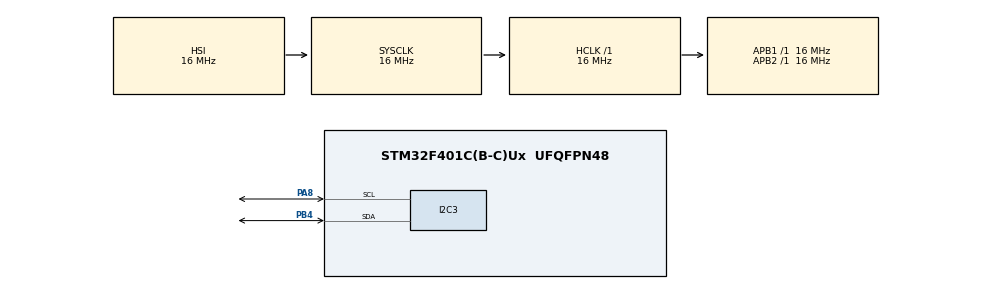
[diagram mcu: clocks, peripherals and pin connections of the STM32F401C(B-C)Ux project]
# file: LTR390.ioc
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FREERTOS.Tasks01=defaultTask,24,128,StartDefaultTask,Default,NULL,Dynamic,NULL,NULL
FREERTOS.configUSE_NEWLIB_REENTRANT=1
Mcu.Family=STM32F4
Mcu.Name=STM32F401C(B-C)Ux
Mcu.Package=UFQFPN48
NVIC.I2C3_ER_IRQn=true\:5\:0\:false\:false\:true\:true\:true\:true\:true
NVIC.I2C3_EV_IRQn=true\:5\:0\:false\:false\:true\:true\:true\:true\:true
NVIC.PriorityGroup=NVIC_PRIORITYGROUP_4
NVIC.TIM4_IRQn=true\:15\:0\:false\:false\:true\:false\:false\:true\:true
NVIC.TimeBase=TIM4_IRQn
NVIC.TimeBaseIP=TIM4
PA13.Mode=Trace_Asynchronous_SW
PA13.Signal=SYS_JTMS-SWDIO
PA14.Mode=Trace_Asynchronous_SW
PA14.Signal=SYS_JTCK-SWCLK
PA8.Mode=I2C
PA8.Signal=I2C3_SCL
PB3.Mode=Trace_Asynchronous_SW
PB3.Signal=SYS_JTDO-SWO
PB4.Mode=I2C
PB4.Signal=I2C3_SDA
ProjectManager.HeapSize=0x200
ProjectManager.StackSize=0x400
ProjectManager.TargetToolchain=STM32CubeIDE
RCC.AHBFreq_Value=16000000
RCC.APB1Freq_Value=16000000
RCC.APB2Freq_Value=16000000
RCC.CortexFreq_Value=16000000
RCC.HSE_VALUE=25000000
RCC.HSI_VALUE=16000000
RCC.LSE_VALUE=32768
RCC.SYSCLKFreq_VALUE=16000000
RCC.VCOOutputFreq_Value=192000000
VP_FREERTOS_VS_CMSIS_V2.Mode=CMSIS_V2
VP_SYS_VS_tim4.Mode=TIM4
board=custom

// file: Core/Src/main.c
/* USER CODE BEGIN Header */
/**
  ******************************************************************************
  * @file           : main.c
  * @brief          : Main program body
  ******************************************************************************
  * @attention
  *
  * Copyright (c) 2026 STMicroelectronics.
  * All rights reserved.
  *
  * This software is licensed under terms that can be found in the LICENSE file
  * in the root directory of this software component.
  * If no LICENSE file comes with this software, it is provided AS-IS.
  *
  ******************************************************************************
  */
/* USER CODE END Header */
#include "main.h"
#include "cmsis_os.h"

/* USER CODE BEGIN Includes */
#include "LTR390.h"
/* USER CODE END Includes */

I2C_HandleTypeDef hi2c3;

/* Definitions for defaultTask */
osThreadId_t defaultTaskHandle;
const osThreadAttr_t defaultTask_attributes = {
  .name = "defaultTask",
  .stack_size = 128 * 4,
  .priority = (osPriority_t) osPriorityNormal,
};
/* USER CODE BEGIN PV */
volatile uint32_t uv340 = 0;
/* USER CODE END PV */

void SystemClock_Config(void);
static void MX_GPIO_Init(void);
static void MX_I2C3_Init(void);
void StartDefaultTask(void *argument);

int main(void)
{

  /* MCU Configuration--------------------------------------------------------*/

  /* Reset of all peripherals, Initializes the Flash interface and the Systick. */
  HAL_Init();

  /* Configure the system clock */
  SystemClock_Config();

  /* Initialize all configured peripherals */
  MX_GPIO_Init();
  MX_I2C3_Init();

  /* Init scheduler */
  osKernelInitialize();

  /* Create the thread(s) */
  /* creation of defaultTask */
  defaultTaskHandle = osThreadNew(StartDefaultTask, NULL, &defaultTask_attributes);

  /* Start scheduler */
  osKernelStart();

  /* We should never get here as control is now taken by the scheduler */

  /* Infinite loop */
  while (1)
  {

  }
}

void SystemClock_Config(void)
{
  RCC_OscInitTypeDef RCC_OscInitStruct = {0};
  RCC_ClkInitTypeDef RCC_ClkInitStruct = {0};

  /** Configure the main internal regulator output voltage
  */
  __HAL_RCC_PWR_CLK_ENABLE();
  __HAL_PWR_VOLTAGESCALING_CONFIG(PWR_REGULATOR_VOLTAGE_SCALE2);

  /** Initializes the RCC Oscillators according to the specified parameters
  * in the RCC_OscInitTypeDef structure.
  */
  RCC_OscInitStruct.OscillatorType = RCC_OSCILLATORTYPE_HSI;
  RCC_OscInitStruct.HSIState = RCC_HSI_ON;
  RCC_OscInitStruct.HSICalibrationValue = RCC_HSICALIBRATION_DEFAULT;
  RCC_OscInitStruct.PLL.PLLState = RCC_PLL_NONE;
  if (HAL_RCC_OscConfig(&RCC_OscInitStruct) != HAL_OK)
  {
    Error_Handler();
  }

  /** Initializes the CPU, AHB and APB buses clocks
  */
  RCC_ClkInitStruct.ClockType = RCC_CLOCKTYPE_HCLK|RCC_CLOCKTYPE_SYSCLK
                              |RCC_CLOCKTYPE_PCLK1|RCC_CLOCKTYPE_PCLK2;
  RCC_ClkInitStruct.SYSCLKSource = RCC_SYSCLKSOURCE_HSI;
  RCC_ClkInitStruct.AHBCLKDivider = RCC_SYSCLK_DIV1;
  RCC_ClkInitStruct.APB1CLKDivider = RCC_HCLK_DIV1;
  RCC_ClkInitStruct.APB2CLKDivider = RCC_HCLK_DIV1;

  if (HAL_RCC_ClockConfig(&RCC_ClkInitStruct, FLASH_LATENCY_0) != HAL_OK)
  {
    Error_Handler();
  }
}

static void MX_I2C3_Init(void)
{

  hi2c3.Instance = I2C3;
  hi2c3.Init.ClockSpeed = 100000;
  hi2c3.Init.DutyCycle = I2C_DUTYCYCLE_2;
  hi2c3.Init.OwnAddress1 = 0;
  hi2c3.Init.AddressingMode = I2C_ADDRESSINGMODE_7BIT;
  hi2c3.Init.DualAddressMode = I2C_DUALADDRESS_DISABLE;
  hi2c3.Init.OwnAddress2 = 0;
  hi2c3.Init.GeneralCallMode = I2C_GENERALCALL_DISABLE;
  hi2c3.Init.NoStretchMode = I2C_NOSTRETCH_DISABLE;
  if (HAL_I2C_Init(&hi2c3) != HAL_OK)
  {
    Error_Handler();
  }

}

static void MX_GPIO_Init(void)
{

  /* GPIO Ports Clock Enable */
  __HAL_RCC_GPIOA_CLK_ENABLE();
  __HAL_RCC_GPIOB_CLK_ENABLE();

}

void StartDefaultTask(void *argument)
{
  /* USER CODE BEGIN 5 */
  /* Infinite loop */
//  for(;;)
//  {
//    osDelay(1);
//  }/

	LTR390_HandleTypeDef ltr;

	    LTR390_Init(&ltr, &hi2c3);

	    if(!LTR390_Begin(&ltr))
	    {
	        Error_Handler();
	    }

	    LTR390_SetMode(&ltr, LTR390_MODE_UVS);
	    LTR390_SetGain(&ltr, LTR390_GAIN_18);
	    LTR390_SetResolution(&ltr, LTR390_RESOLUTION_20BIT);

	    for (;;)
	    {
	        if (LTR390_NewDataAvailable(&ltr))
	        {
	            uv340 = LTR390_ReadUVS(&ltr);
	        }

	        osDelay(1000);
	    }
  /* USER CODE END 5 */
}

void HAL_TIM_PeriodElapsedCallback(TIM_HandleTypeDef *htim)
{
  if (htim->Instance == TIM4)
  {
    HAL_IncTick();
  }
}

void Error_Handler(void)
{
  __disable_irq();
  while (1)
  {
  }
}
